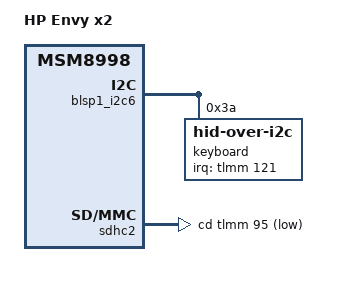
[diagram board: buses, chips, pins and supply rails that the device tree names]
// SPDX-License-Identifier: GPL-2.0
/* Copyright (c) 2019, Jeffrey Hugo. All rights reserved. */

/dts-v1/;

#include "msm8998-clamshell.dtsi"

/ {
	model = "HP Envy x2";
	compatible = "hp,envy-x2", "qcom,msm8998";
	chassis-type = "convertible";
};

&blsp1_i2c6 {
	status = "okay";

	keyboard@3a {
		compatible = "hid-over-i2c";
		reg = <0x3a>;
		pinctrl-names = "default";
		pinctrl-0 = <&touchpad>;

		interrupt-parent = <&tlmm>;
		interrupts = <121 IRQ_TYPE_LEVEL_LOW>;

		hid-descr-addr = <0x0001>;
	};
};

&sdhc2 {
	cd-gpios = <&tlmm 95 GPIO_ACTIVE_LOW>;
};
